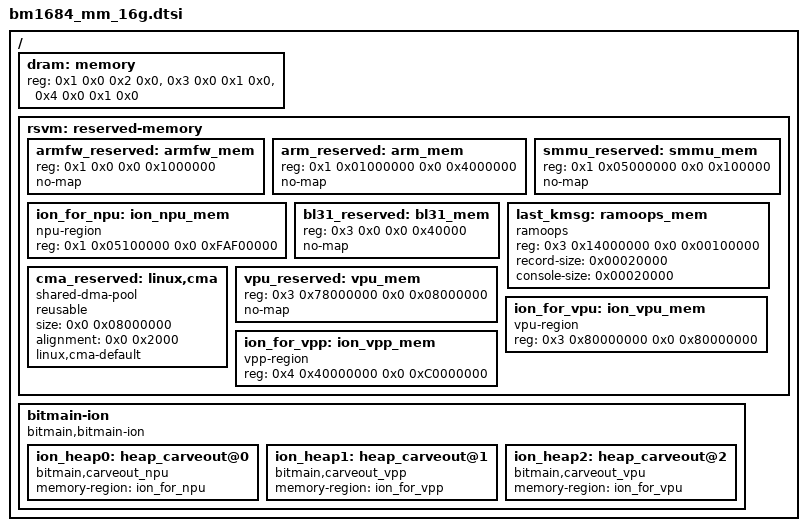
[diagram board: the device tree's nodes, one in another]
/ {
	dram: memory {
		reg = <0x1 0x0 0x2 0x0>, // 8G
		      <0x3 0x0 0x1 0x0>, // 4G
		      <0x4 0x0 0x1 0x0>; // 4G
		device_type = "memory";
	};

	rsvm: reserved-memory {
		#address-cells = <0x2>;
		#size-cells = <0x2>;
		ranges;

		armfw_reserved: armfw_mem {
			reg = <0x1 0x0 0x0 0x1000000>; // 16M
			no-map;
		};

		arm_reserved: arm_mem {
			reg = <0x1 0x01000000 0x0 0x4000000>; // 64M
			no-map;
		};

		smmu_reserved: smmu_mem {
			reg = <0x1 0x05000000 0x0 0x100000>; // 1M
			no-map;
		};


		ion_for_npu: ion_npu_mem {
			compatible = "npu-region";
			reg = <0x1 0x05100000 0x0 0xFAF00000>; // 3.92GB
		};

		bl31_reserved: bl31_mem {
			reg = <0x3 0x0 0x0 0x40000>; // 256KB
			no-map;
		};

		// 0x310000000 - 0x314000000 is for crash kernel

		last_kmsg: ramoops_mem {
			compatible = "ramoops";
			reg = <0x3 0x14000000 0x0 0x00100000>;
			record-size = <0x00020000>;
			console-size = <0x00020000>;
		};

		cma_reserved: linux,cma {
			compatible = "shared-dma-pool";
			reusable;
			size = <0x0 0x08000000>; // 128MB
			alignment = <0x0 0x2000>; // 8KB
			linux,cma-default;
		};

		vpu_reserved: vpu_mem {
			reg = <0x3 0x78000000 0x0 0x08000000>; // 128M, for VPU firmware
			no-map;
		};

		ion_for_vpu: ion_vpu_mem {
			compatible = "vpu-region";
			reg = <0x3 0x80000000 0x0 0x80000000>; // 2G, for VPU
		};

		ion_for_vpp: ion_vpp_mem {
			compatible = "vpp-region";
			reg = <0x4 0x40000000 0x0 0xC0000000>; // 3G, for VPP/JPU
		};
	};

	bitmain-ion {
		compatible = "bitmain,bitmain-ion";

		ion_heap0: heap_carveout@0 {
			compatible = "bitmain,carveout_npu";
			memory-region = <&ion_for_npu>;
		};

		ion_heap1: heap_carveout@1 {
			compatible = "bitmain,carveout_vpp";
			memory-region = <&ion_for_vpp>;
		};

		ion_heap2: heap_carveout@2 {
			compatible = "bitmain,carveout_vpu";
			memory-region = <&ion_for_vpu>;
		};
	};
};
